VERSION ""

NS_ :

BS_:

BU_: XXX

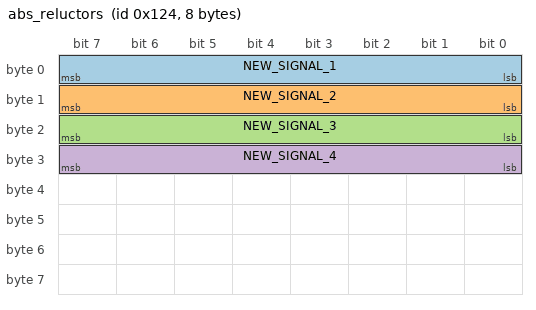
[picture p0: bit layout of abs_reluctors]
BO_ 292 abs_reluctors: 8 XXX
 SG_ NEW_SIGNAL_1 : 7|8@0+ (1,0) [0|255] "" XXX
 SG_ NEW_SIGNAL_2 : 15|8@0+ (1,0) [0|255] "" XXX
 SG_ NEW_SIGNAL_3 : 23|8@0+ (1,0) [0|255] "" XXX
 SG_ NEW_SIGNAL_4 : 31|8@0+ (1,0) [0|255] "" XXX
